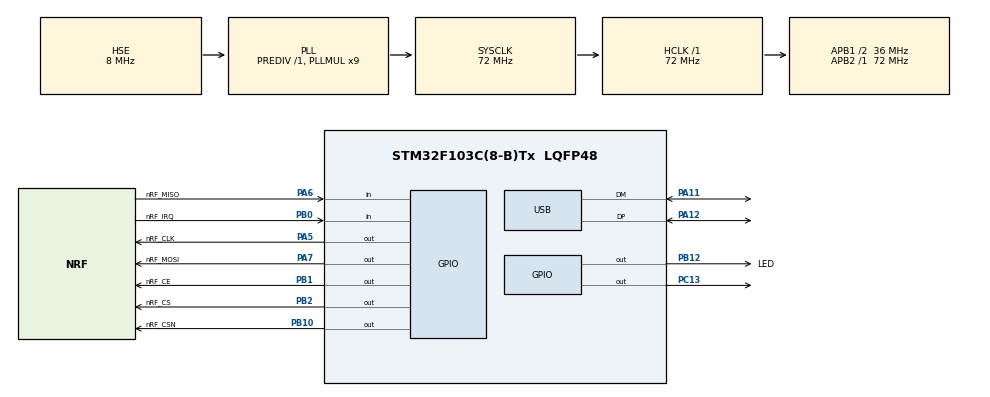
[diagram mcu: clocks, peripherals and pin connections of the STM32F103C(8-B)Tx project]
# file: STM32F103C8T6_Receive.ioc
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Mcu.Family=STM32F1
Mcu.Name=STM32F103C(8-B)Tx
Mcu.Package=LQFP48
NVIC.PriorityGroup=NVIC_PRIORITYGROUP_4
NVIC.TIM2_IRQn=true\:0\:0\:false\:false\:true\:true\:true\:true
NVIC.USB_LP_CAN1_RX0_IRQn=true\:0\:0\:false\:false\:true\:false\:true\:true
PA11.Mode=Device
PA11.Signal=USB_DM
PA12.Mode=Device
PA12.Signal=USB_DP
PA13.Mode=Serial_Wire
PA13.Signal=SYS_JTMS-SWDIO
PA14.Mode=Serial_Wire
PA14.Signal=SYS_JTCK-SWCLK
PA5.GPIO_Label=nRF_CLK
PA5.GPIO_PuPd=GPIO_PULLDOWN
PA5.GPIO_Speed=GPIO_SPEED_FREQ_HIGH
PA5.Signal=GPIO_Output
PA6.GPIO_Label=nRF_MISO
PA6.Signal=GPIO_Input
PA7.GPIO_Label=nRF_MOSI
PA7.GPIO_Speed=GPIO_SPEED_FREQ_HIGH
PA7.Signal=GPIO_Output
PB0.GPIO_Label=nRF_IRQ
PB0.Signal=GPIO_Input
PB1.GPIO_Label=nRF_CE
PB1.GPIO_PuPd=GPIO_PULLUP
PB1.GPIO_Speed=GPIO_SPEED_FREQ_HIGH
PB1.PinState=GPIO_PIN_SET
PB1.Signal=GPIO_Output
PB10.GPIO_Label=nRF_CSN
PB10.GPIO_PuPd=GPIO_PULLDOWN
PB10.Signal=GPIO_Output
PB12.GPIO_Label=LED
PB12.GPIO_PuPd=GPIO_PULLUP
PB12.PinState=GPIO_PIN_SET
PB12.Signal=GPIO_Output
PB2.GPIO_Label=nRF_CS
PB2.GPIO_PuPd=GPIO_PULLDOWN
PB2.Signal=GPIO_Output
PC13-TAMPER-RTC.GPIO_PuPd=GPIO_PULLUP
PC13-TAMPER-RTC.PinState=GPIO_PIN_SET
PC13-TAMPER-RTC.Signal=GPIO_Output
PC14-OSC32_IN.Mode=LSE-External-Oscillator
PC14-OSC32_IN.Signal=RCC_OSC32_IN
PC15-OSC32_OUT.Mode=LSE-External-Oscillator
PC15-OSC32_OUT.Signal=RCC_OSC32_OUT
PD0-OSC_IN.Mode=HSE-External-Oscillator
PD0-OSC_IN.Signal=RCC_OSC_IN
PD1-OSC_OUT.Mode=HSE-External-Oscillator
PD1-OSC_OUT.Signal=RCC_OSC_OUT
ProjectManager.HeapSize=0x200
ProjectManager.StackSize=0x400
ProjectManager.TargetToolchain=MDK-ARM V5.32
RCC.AHBFreq_Value=72000000
RCC.APB1CLKDivider=RCC_HCLK_DIV2
RCC.APB1Freq_Value=36000000
RCC.APB1TimFreq_Value=72000000
RCC.APB2Freq_Value=72000000
RCC.APB2TimFreq_Value=72000000
RCC.HCLKFreq_Value=72000000
RCC.PLLMUL=RCC_PLL_MUL9
RCC.PLLSourceVirtual=RCC_PLLSOURCE_HSE
RCC.SYSCLKFreq_VALUE=72000000
RCC.SYSCLKSource=RCC_SYSCLKSOURCE_PLLCLK
RCC.USBFreq_Value=48000000
RCC.USBPrescaler=RCC_USBCLKSOURCE_PLL_DIV1_5
TIM2.AutoReloadPreload=TIM_AUTORELOAD_PRELOAD_ENABLE
TIM2.Period=1000-1
TIM2.Prescaler=72-1
USB_DEVICE.CLASS_NAME_FS=HID
USB_DEVICE.HID_FS_BINTERVAL=1
USB_DEVICE.USBD_MAX_STR_DESC_SIZ=4
USB_DEVICE.VirtualMode=Hid
USB_DEVICE.VirtualModeFS=Hid_FS
VP_TIM2_VS_ClockSourceINT.Mode=Internal
VP_USB_DEVICE_VS_USB_DEVICE_HID_FS.Mode=HID_FS
board=custom

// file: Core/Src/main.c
/* USER CODE BEGIN Header */
/**
  ******************************************************************************
  * @file           : main.c
  * @brief          : Main program body
  ******************************************************************************
  * @attention
  *
  * Copyright (c) 2023 STMicroelectronics.
  * All rights reserved.
  *
  * This software is licensed under terms that can be found in the LICENSE file
  * in the root directory of this software component.
  * If no LICENSE file comes with this software, it is provided AS-IS.
  *
  ******************************************************************************
  */
/* USER CODE END Header */
#include "main.h"
#include "tim.h"
#include "usb_device.h"
#include "gpio.h"

/* USER CODE BEGIN Includes */
#include "SystemOS.h"

/* USER CODE END Includes */

void SystemClock_Config(void);

int main(void)
{

  /* MCU Configuration--------------------------------------------------------*/

  /* Reset of all peripherals, Initializes the Flash interface and the Systick. */
  HAL_Init();

  /* Configure the system clock */
  SystemClock_Config();

  /* Initialize all configured peripherals */
  MX_GPIO_Init();
  MX_USB_DEVICE_Init();
  MX_TIM2_Init();
  /* USER CODE BEGIN 2 */
//	HAL_TIM_Base_Start_IT(&htim2);

	SystemOS_Init();

  /* USER CODE END 2 */

  /* Infinite loop */
  /* USER CODE BEGIN WHILE */
  while (1)
  {
//参数x 代表鼠标应当左右移动的值，大于0左移，小于0右移
//参数y 代表鼠标应当上下移动的值，大于0下移，小于0上移
//	MouseMove(-15, 0);
//	  MouseUpdate();
//	MouseMove(0, 0);
//	  MouseUpdate();
//	HAL_Delay(1000);
//	MouseMove(15, 0);
//	  MouseUpdate();
//	MouseMove(0, 0);
//	  MouseUpdate();
//	HAL_Delay(1000);

	SystemOS_Loop();

//	HAL_GPIO_TogglePin(GPIOC, GPIO_PIN_13);
    /* USER CODE END WHILE */

  }
}

void SystemClock_Config(void)
{
  RCC_OscInitTypeDef RCC_OscInitStruct = {0};
  RCC_ClkInitTypeDef RCC_ClkInitStruct = {0};
  RCC_PeriphCLKInitTypeDef PeriphClkInit = {0};

  /** Initializes the RCC Oscillators according to the specified parameters
  * in the RCC_OscInitTypeDef structure.
  */
  RCC_OscInitStruct.OscillatorType = RCC_OSCILLATORTYPE_HSE;
  RCC_OscInitStruct.HSEState = RCC_HSE_ON;
  RCC_OscInitStruct.HSEPredivValue = RCC_HSE_PREDIV_DIV1;
  RCC_OscInitStruct.HSIState = RCC_HSI_ON;
  RCC_OscInitStruct.PLL.PLLState = RCC_PLL_ON;
  RCC_OscInitStruct.PLL.PLLSource = RCC_PLLSOURCE_HSE;
  RCC_OscInitStruct.PLL.PLLMUL = RCC_PLL_MUL9;
  if (HAL_RCC_OscConfig(&RCC_OscInitStruct) != HAL_OK)
  {
    Error_Handler();
  }

  /** Initializes the CPU, AHB and APB buses clocks
  */
  RCC_ClkInitStruct.ClockType = RCC_CLOCKTYPE_HCLK|RCC_CLOCKTYPE_SYSCLK
                              |RCC_CLOCKTYPE_PCLK1|RCC_CLOCKTYPE_PCLK2;
  RCC_ClkInitStruct.SYSCLKSource = RCC_SYSCLKSOURCE_PLLCLK;
  RCC_ClkInitStruct.AHBCLKDivider = RCC_SYSCLK_DIV1;
  RCC_ClkInitStruct.APB1CLKDivider = RCC_HCLK_DIV2;
  RCC_ClkInitStruct.APB2CLKDivider = RCC_HCLK_DIV1;

  if (HAL_RCC_ClockConfig(&RCC_ClkInitStruct, FLASH_LATENCY_2) != HAL_OK)
  {
    Error_Handler();
  }
  PeriphClkInit.PeriphClockSelection = RCC_PERIPHCLK_USB;
  PeriphClkInit.UsbClockSelection = RCC_USBCLKSOURCE_PLL_DIV1_5;
  if (HAL_RCCEx_PeriphCLKConfig(&PeriphClkInit) != HAL_OK)
  {
    Error_Handler();
  }
}

void Error_Handler(void)
{
  __disable_irq();
  while (1)
  {
  }
}
